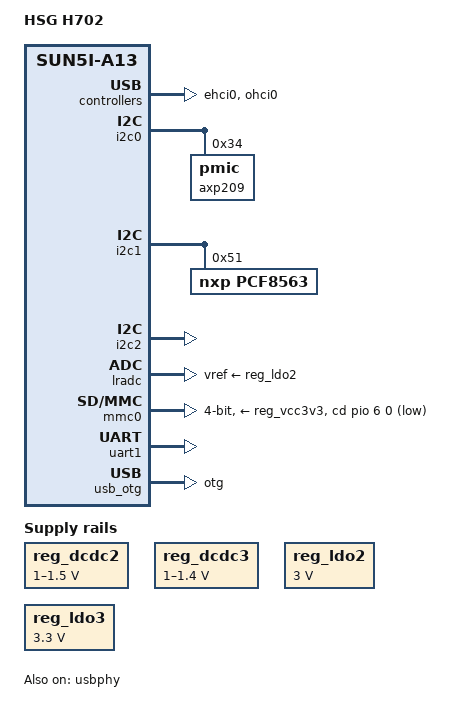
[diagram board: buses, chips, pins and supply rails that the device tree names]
/dts-v1/;
#include "sun5i-a13.dtsi"
#include "sunxi-common-regulators.dtsi"
#include <dt-bindings/gpio/gpio.h>
#include <dt-bindings/input/input.h>
/ {
	model = "HSG H702";
	compatible = "hsg,h702", "allwinner,sun5i-a13";
	aliases {
		serial0 = &uart1;
	};
	chosen {
		stdout-path = "serial0:115200n8";
	};
};
&cpu0 {
	cpu-supply = <&reg_dcdc2>;
};
&ehci0 {
	status = "okay";
};
&i2c0 {
	status = "okay";
	axp209: pmic@34 {
		reg = <0x34>;
		interrupts = <0>;
	};
};
&i2c1 {
	status = "okay";
	pcf8563: rtc@51 {
		compatible = "nxp,pcf8563";
		reg = <0x51>;
	};
};
&i2c2 {
	status = "okay";
};
&lradc {
	vref-supply = <&reg_ldo2>;
	status = "okay";
	button-200 {
		label = "Volume Up";
		linux,code = <KEY_VOLUMEUP>;
		channel = <0>;
		voltage = <200000>;
	};
	button-400 {
		label = "Volume Down";
		linux,code = <KEY_VOLUMEDOWN>;
		channel = <0>;
		voltage = <400000>;
	};
};
&mmc0 {
	vmmc-supply = <&reg_vcc3v3>;
	bus-width = <4>;
	cd-gpios = <&pio 6 0 GPIO_ACTIVE_LOW>;  
	status = "okay";
};
&ohci0 {
	status = "okay";
};
&otg_sram {
	status = "okay";
};
#include "axp209.dtsi"
&reg_dcdc2 {
	regulator-always-on;
	regulator-min-microvolt = <1000000>;
	regulator-max-microvolt = <1500000>;
	regulator-name = "vdd-cpu";
};
&reg_dcdc3 {
	regulator-always-on;
	regulator-min-microvolt = <1000000>;
	regulator-max-microvolt = <1400000>;
	regulator-name = "vdd-int-dll";
};
&reg_ldo1 {
	regulator-name = "vdd-rtc";
};
&reg_ldo2 {
	regulator-always-on;
	regulator-min-microvolt = <3000000>;
	regulator-max-microvolt = <3000000>;
	regulator-name = "avcc";
};
&reg_ldo3 {
	regulator-min-microvolt = <3300000>;
	regulator-max-microvolt = <3300000>;
	regulator-name = "vcc-wifi";
};
&reg_usb0_vbus {
	gpio = <&pio 6 12 GPIO_ACTIVE_HIGH>;  
	status = "okay";
};
&uart1 {
	pinctrl-names = "default";
	pinctrl-0 = <&uart1_pg_pins>;
	status = "okay";
};
&usb_otg {
	dr_mode = "otg";
	status = "okay";
};
&usbphy {
	usb0_id_det-gpios = <&pio 6 2 (GPIO_ACTIVE_HIGH | GPIO_PULL_UP)>;  
	usb0_vbus_det-gpios = <&pio 6 1 GPIO_ACTIVE_HIGH>;  
	usb0_vbus-supply = <&reg_usb0_vbus>;
	usb1_vbus-supply = <&reg_ldo3>;
	status = "okay";
};
